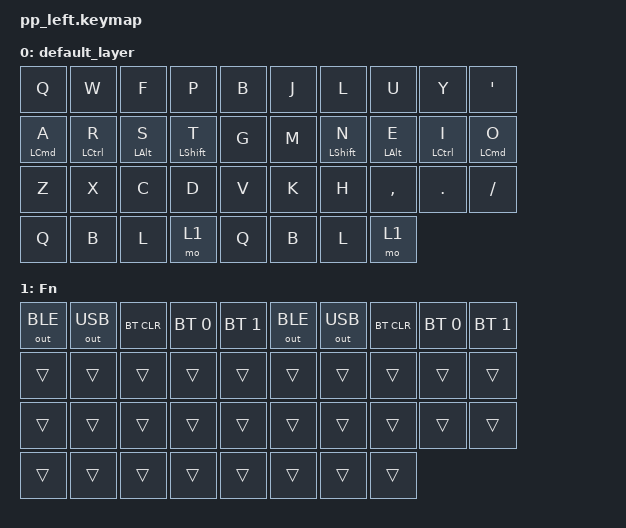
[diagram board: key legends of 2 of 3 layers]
#include <behaviors.dtsi>
#include <dt-bindings/zmk/bt.h>
#include <dt-bindings/zmk/keys.h>
#include <dt-bindings/zmk/outputs.h>
#include <dt-bindings/zmk/pointing.h>
#include <input/processors.dtsi>

&mt {
    tapping-term-ms = <400>;
};

&pmw3610_listener {
    input-processors = <&zip_temp_layer 3 500>;

    scroller {
        layers = <4>;
        input-processors = <&zip_xy_to_scroll_mapper>;
    };
};

/ {
    combos {
        compatible = "zmk,combos";

        studio_unlock_combo {
            timeout-ms = <1000>;
            key-positions = <30 31>;
            bindings = <&studio_unlock>;
        };

        studio_unlock_combo_right {
            timeout-ms = <1000>;
            key-positions = <36 37>;
            bindings = <&studio_unlock>;
        };


    };

    keymap {
        compatible = "zmk,keymap";

        default_layer { // Layer 0
            bindings = <
                &kp Q    &kp W    &kp F    &kp P    &kp B    &kp J    &kp L    &kp U    &kp Y   &kp APOS
                &mt LCMD A    &mt LCTRL R    &mt LALT S    &mt LSHIFT T    &kp G    &kp M    &mt LSHIFT N    &mt LALT E    &mt LCTRL I    &mt LCMD O
                &kp Z    &kp X    &kp C    &kp D    &kp V    &kp K    &kp H    &kp COMMA    &kp PERIOD    &kp SLASH
                &kp Q    &kp B    &kp L    &mo 1    &kp Q    &kp B    &kp L    &mo 1
            >;
        };

        fn_layer {
            display-name = "Fn";
            bindings = <
                &out OUT_BLE  &out OUT_USB  &bt BT_CLR  &bt BT_SEL 0  &bt BT_SEL 1    &out OUT_BLE  &out OUT_USB  &bt BT_CLR  &bt BT_SEL 0  &bt BT_SEL 1
                &trans        &trans       &trans        &trans        &trans          &trans        &trans       &trans        &trans        &trans
                &trans        &trans       &trans        &trans        &trans          &trans        &trans       &trans        &trans        &trans
                &trans        &trans       &trans        &trans        &trans          &trans        &trans       &trans
            >;
        };

        num_layer {
            display-name = "Num";
            bindings = <
                &kp LBKT  &kp N7  &kp N8  &kp N9  &kp RBKT     &trans          &trans        &trans       &trans        &trans        &trans
                &kp SEMI  &kp N4  &kp N5  &kp N6  &kp EQUAL          &trans        &trans       &trans        &trans        &trans
                &kp GRAVE &kp N1  &kp N2  &kp N3  &kp BSLH          &trans        &trans       &trans        &trans        &trans
                &trans        &trans       &trans        &trans        &trans          &trans        &trans       &trans
            >;
        };

        extra1 {
            status = "reserved";
        };

        extra2 {
            status = "reserved";
        };

        extra3 {
            status = "reserved";
        };

        extra4 {
            status = "reserved";
        };

        extra5 {
            status = "reserved";
        };
    };
 };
